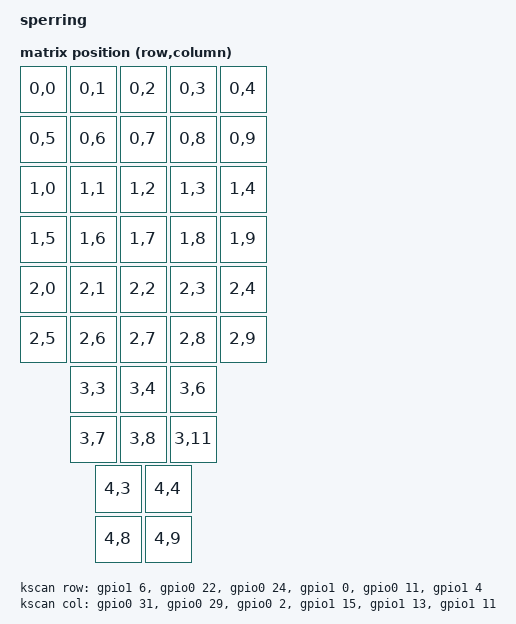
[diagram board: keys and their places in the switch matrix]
// This file was generated from a template. Edit it to match your keyboard.
// See https://docs.zephyrproject.org/4.1.0/hardware/porting/board_porting.html
// and https://zmk.dev/docs/development/hardware-integration/new-shield for more
// instructions.

/dts-v1/;
#include <dt-bindings/zmk/matrix_transform.h>

#include "sperring-pinctrl.dtsi"
#include "sperring-layouts.dtsi"

/ {
    model = "sperring";
    compatible = "sperring";

    chosen {
        zmk,physical-layout = &default_layout;
    };

    kscan: kscan {
        // If the hardware does not use a switch matrix, change this to the
        // appropriate driver and update the properties below to match.
        // See https://zmk.dev/docs/config/kscan for supported key scan drivers.
        compatible = "zmk,kscan-gpio-matrix";
        // Set this to "col2row" or "row2col" to match the hardware. If using
        // "row2col", change the col-gpios in the _left.overlay and _right.overlay
        // files to (GPIO_ACTIVE_HIGH | GPIO_PULL_DOWN) and the row-gpios here to
        // GPIO_ACTIVE_HIGH.
        diode-direction = "col2row";
        wakeup-source;

        // Replace these comments with the GPIO pins in the matrix.
        // See https://zmk.dev/docs/development/hardware-integration/new-shield#shield-overlays

        /* Ordered row 6 to row 1, as you listed them */
        row-gpios =
            <&gpio1 6 (GPIO_ACTIVE_HIGH | GPIO_PULL_DOWN)>,  /* row 6 -> 106 */
            <&gpio0 22 (GPIO_ACTIVE_HIGH | GPIO_PULL_DOWN)>, /* row 5 -> 022 */
            <&gpio0 24 (GPIO_ACTIVE_HIGH | GPIO_PULL_DOWN)>, /* row 4 -> 024 */
            <&gpio1 0 (GPIO_ACTIVE_HIGH | GPIO_PULL_DOWN)>,  /* row 3 -> 100 */
            <&gpio0 11 (GPIO_ACTIVE_HIGH | GPIO_PULL_DOWN)>, /* row 2 -> 011 */
            <&gpio1 4 (GPIO_ACTIVE_HIGH | GPIO_PULL_DOWN)>;  /* row 1 -> 104 */

        /* Ordered column 1 to column 6 */
        col-gpios =
            <&gpio0 31 GPIO_ACTIVE_HIGH>, /* col 1 -> 031 */
            <&gpio0 29 GPIO_ACTIVE_HIGH>, /* col 2 -> 029 */
            <&gpio0 2  GPIO_ACTIVE_HIGH>, /* col 3 -> 002 */
            <&gpio1 15 GPIO_ACTIVE_HIGH>, /* col 4 -> 115 */
            <&gpio1 13 GPIO_ACTIVE_HIGH>, /* col 5 -> 113 */
            <&gpio1 11 GPIO_ACTIVE_HIGH>; /* col 6 -> 111 */
    };

    default_transform: default_transform {
        // See https://zmk.dev/docs/development/hardware-integration/new-shield#matrix-transform
        // for how to configure this
        compatible = "zmk,matrix-transform";
        rows = <5>;
        columns = <12>;

        map = <
            /* Row 0 */ RC(0,0) RC(0,1) RC(0,2) RC(0,3) RC(0,4)
                       RC(0,5) RC(0,6) RC(0,7) RC(0,8) RC(0,9)

            /* Row 1 */ RC(1,0) RC(1,1) RC(1,2) RC(1,3) RC(1,4)
                       RC(1,5) RC(1,6) RC(1,7) RC(1,8) RC(1,9)

            /* Row 2 */ RC(2,0) RC(2,1) RC(2,2) RC(2,3) RC(2,4)
                       RC(2,5) RC(2,6) RC(2,7) RC(2,8) RC(2,9)

            /* Row 3: 3 keys per half */
                       RC(3,3) RC(3,4) RC(3,6)
                       RC(3,7) RC(3,8) RC(3,11)
                       

            /* Row 4: 2 keys per half */
                       RC(4,3) RC(4,4)
                       RC(4,8) RC(4,9)
        >;
    };
};
